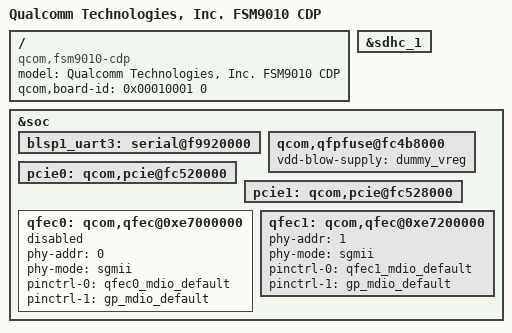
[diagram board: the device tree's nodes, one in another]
/* Copyright (c) 2014-2015, The Linux Foundation. All rights reserved.
 *
 * This program is free software; you can redistribute it and/or modify
 * it under the terms of the GNU General Public License version 2 and
 * only version 2 as published by the Free Software Foundation.
 *
 * This program is distributed in the hope that it will be useful,
 * but WITHOUT ANY WARRANTY; without even the implied warranty of
 * MERCHANTABILITY or FITNESS FOR A PARTICULAR PURPOSE.  See the
 * GNU General Public License for more details.
 */

/dts-v1/;

#include "fsm9010.dtsi"

/ {
	model = "Qualcomm Technologies, Inc. FSM9010 CDP";
	compatible = "qcom,fsm9010-cdp", "qcom,fsm9010", "qcom,cdp";
	qcom,board-id = <0x00010001 0>;
};

&sdhc_1 {
	status = "ok";
};

&soc {
	blsp1_uart3: serial@f9920000 {
		status = "ok";
	};

	qcom,qfpfuse@fc4b8000 {
		status = "ok";
		vdd-blow-supply = <&dummy_vreg>;
	};

	pcie0: qcom,pcie@fc520000 {
		status = "ok";
	};

	pcie1: qcom,pcie@fc528000 {
		status = "ok";
	};

	qfec0: qcom,qfec@0xe7000000 {
		phy-addr = <0>;
		phy-mode = "sgmii";
		pinctrl-names = "active", "deactive";
		pinctrl-0 = <&qfec0_mdio_default>;
		pinctrl-1 = <&gp_mdio_default>;
		status = "disabled";
	};


	qfec1: qcom,qfec@0xe7200000 {
		phy-addr = <1>;
		phy-mode = "sgmii";
		pinctrl-names = "active", "deactive";
		pinctrl-0 = <&qfec1_mdio_default>;
		pinctrl-1 = <&gp_mdio_default>;
		status = "ok";
	};

};
